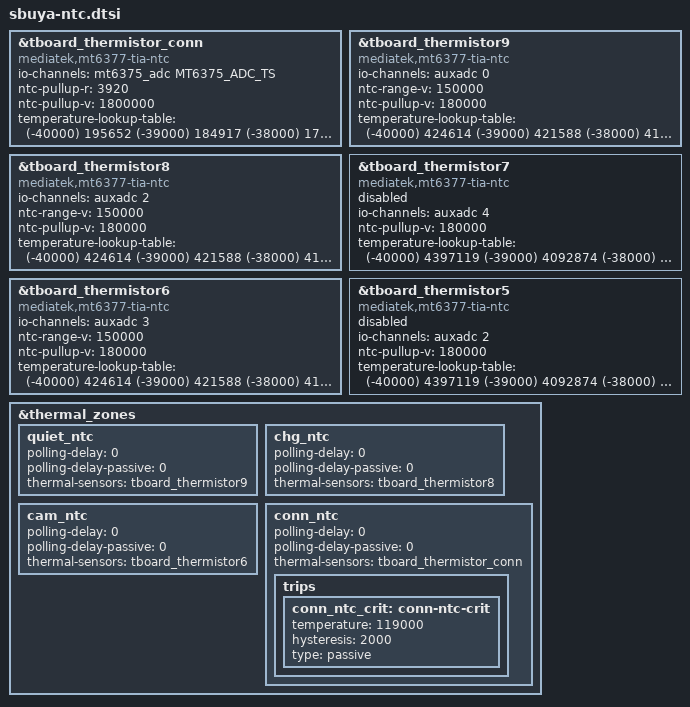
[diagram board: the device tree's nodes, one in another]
#include <dt-bindings/iio/mt635x-auxadc.h>
#include <dt-bindings/iio/adc/mediatek,mt6375_adc.h>

&tboard_thermistor_conn {
	compatible = "mediatek,mt6377-tia-ntc";
	#thermal-sensor-cells = <0>;
	io-channels = <&mt6375_adc MT6375_ADC_TS>;
	io-channel-names = "CONN_NTC";
	ntc-pullup-r = <3920>;
	ntc-pullup-v = <1800000>;
	temperature-lookup-table = <
		(-40000) 195652
		(-39000) 184917
		(-38000) 174845
		(-37000) 165391
		(-36000) 156512
		(-35000) 148171
		(-34000) 140330
		(-33000) 132957
		(-32000) 126021
		(-31000) 119493
		(-30000) 113347
		(-29000) 107564
		(-28000) 102115
		(-27000) 96977
		(-26000) 92131
		(-25000) 87558
		(-24000) 83242
		(-23000) 79166
		(-22000) 75315
		(-21000) 71676
		(-20000) 68236
		(-19000) 64990
		(-18000) 61919
		(-17000) 59011
		(-16000) 56257
		(-15000) 53649
		(-14000) 51177
		(-13000) 48834
		(-12000) 46613
		(-11000) 44505
		(-10000) 42506
		(-9000) 40599
		(-8000) 38790
		(-7000) 37072
		(-6000) 35441
		(-5000) 33892
		(-4000) 32419
		(-3000) 31020
		(-2000) 29689
		(-1000) 28423
		0 27218
		1000 26076
		2000 24987
		3000 23950
		4000 22962
		5000 22021
		6000 21123
		7000 20266
		8000 19449
		9000 18669
		10000 17925
		11000 17213
		12000 16534
		13000 15885
		14000 15265
		15000 14673
		16000 14107
		17000 13566
		18000 13048
		19000 12554
		20000 12080
		21000 11628
		22000 11194
		23000 10779
		24000 10381
		25000 10000
		26000 9634
		27000 9283
		28000 8947
		29000 8624
		30000 8314
		31000 8018
		32000 7733
		33000 7460
		34000 7199
		35000 6947
		36000 6706
		37000 6475
		38000 6252
		39000 6039
		40000 5833
		41000 5635
		42000 5445
		43000 5262
		44000 5086
		45000 4916
		46000 4753
		47000 4597
		48000 4446
		49000 4300
		50000 4160
		51000 4026
		52000 3896
		53000 3771
		54000 3651
		55000 3535
		56000 3423
		57000 3315
		58000 3211
		59000 3111
		60000 3014
		61000 2922
		62000 2833
		63000 2748
		64000 2665
		65000 2586
		66000 2509
		67000 2435
		68000 2363
		69000 2294
		70000 2227
		71000 2162
		72000 2100
		73000 2039
		74000 1981
		75000 1924
		76000 1869
		77000 1817
		78000 1765
		79000 1716
		80000 1668
		81000 1622
		82000 1577
		83000 1534
		84000 1492
		85000 1452
		86000 1412
		87000 1374
		88000 1338
		89000 1302
		90000 1268
		91000 1234
		92000 1201
		93000 1170
		94000 1139
		95000 1109
		96000 1080
		97000 1052
		98000 1025
		99000 999
		100000 973
		101000 949
		102000 925
		103000 902
		104000 879
		105000 858
		106000 836
		107000 816
		108000 796
		109000 776
		110000 758
		111000 739
		112000 721
		113000 704
		114000 687
		115000 671
		116000 655
		117000 640
		118000 625
		119000 610
		120000 596
		121000 582
		122000 569
		123000 556
		124000 543
		125000 531>;
};


/*[TN.NJDC] ntc overlay file.start*/
&tboard_thermistor9 {
	compatible = "mediatek,mt6377-tia-ntc";
	io-channels = <&auxadc 0>;
	io-channel-names = "QUIET_NTC";
	ntc-range-v = <150000>;
	ntc-pullup-v = <180000>;
	#thermal-sensor-cells = <0>;
	temperature-lookup-table = <
		(-40000) 424614
		(-39000) 421588
		(-38000) 418409
		(-37000) 415074
		(-36000) 411580
		(-35000) 407925
		(-34000) 404107
		(-33000) 400124
		(-32000) 395975
		(-31000) 391660
		(-30000) 387180
		(-29000) 382534
		(-28000) 377725
		(-27000) 372755
		(-26000) 367626
		(-25000) 362343
		(-24000) 356898
		(-23000) 351308
		(-22000) 345578
		(-21000) 339716
		(-20000) 333729
		(-19000) 327625
		(-18000) 321412
		(-17000) 315100
		(-16000) 308698
		(-15000) 302217
		(-14000) 295666
		(-13000) 289058
		(-12000) 282403
		(-11000) 275712
		(-10000) 268997
		(-9000) 262259
		(-8000) 255520
		(-7000) 248791
		(-6000) 242083
		(-5000) 235407
		(-4000) 228783
		(-3000) 222210
		(-2000) 215698
		(-1000) 209256
		0 202894
		1000 196611
		2000 190423
		3000 184336
		4000 178357
		5000 172491
		6000 166744
		7000 161118
		8000 155618
		9000 150248
		10000 145008
		11000 139902
		12000 134931
		13000 130096
		14000 125397
		15000 120834
		16000 116405
		17000 112112
		18000 107953
		19000 103927
		20000 100033
		21000 96268
		22000 92631
		23000 89118
		24000 85727
		25000 82456
		26000 79302
		27000 76261
		28000 73332
		29000 70511
		30000 67794
		31000 65180
		32000 62665
		33000 60246
		34000 57920
		35000 55683
		36000 53534
		37000 51468
		38000 49483
		39000 47576
		40000 45744
		41000 43987
		42000 42299
		43000 40678
		44000 39122
		45000 37629
		46000 36193
		47000 34816
		48000 33493
		49000 32223
		50000 31005
		51000 29837
		52000 28715
		53000 27639
		54000 26606
		55000 25614
		56000 24663
		57000 23749
		58000 22872
		59000 22029
		60000 21221
		61000 20445
		62000 19699
		63000 18983
		64000 18295
		65000 17635
		66000 17002
		67000 16394
		68000 15810
		69000 15248
		70000 14709
		71000 14189
		72000 13690
		73000 13210
		74000 12748
		75000 12305
		76000 11879
		77000 11470
		78000 11076
		79000 10698
		80000 10333
		81000 9983
		82000 9646
		83000 9321
		84000 9009
		85000 8708
		86000 8419
		87000 8140
		88000 7871
		89000 7613
		90000 7364
		91000 7125
		92000 6894
		93000 6672
		94000 6458
		95000 6252
		96000 6053
		97000 5860
		98000 5675
		99000 5496
		100000 5323
		101000 5157
		102000 4997
		103000 4843
		104000 4694
		105000 4550
		106000 4411
		107000 4277
		108000 4147
		109000 4022
		110000 3902
		111000 3785
		112000 3672
		113000 3563
		114000 3458
		115000 3356
		116000 3258
		117000 3164
		118000 3072
		119000 2984
		120000 2898
		121000 2815
		122000 2735
		123000 2657
		124000 2582
		125000 2509>;
};
&tboard_thermistor8 {
	compatible = "mediatek,mt6377-tia-ntc";
	io-channels = <&auxadc 2>;
	io-channel-names = "CHG_NTC";
	ntc-range-v = <150000>;
	ntc-pullup-v = <180000>;
	#thermal-sensor-cells = <0>;
	temperature-lookup-table = <
		(-40000) 424614
		(-39000) 421588
		(-38000) 418409
		(-37000) 415074
		(-36000) 411580
		(-35000) 407925
		(-34000) 404107
		(-33000) 400124
		(-32000) 395975
		(-31000) 391660
		(-30000) 387180
		(-29000) 382534
		(-28000) 377725
		(-27000) 372755
		(-26000) 367626
		(-25000) 362343
		(-24000) 356898
		(-23000) 351308
		(-22000) 345578
		(-21000) 339716
		(-20000) 333729
		(-19000) 327625
		(-18000) 321412
		(-17000) 315100
		(-16000) 308698
		(-15000) 302217
		(-14000) 295666
		(-13000) 289058
		(-12000) 282403
		(-11000) 275712
		(-10000) 268997
		(-9000) 262259
		(-8000) 255520
		(-7000) 248791
		(-6000) 242083
		(-5000) 235407
		(-4000) 228783
		(-3000) 222210
		(-2000) 215698
		(-1000) 209256
		0 202894
		1000 196611
		2000 190423
		3000 184336
		4000 178357
		5000 172491
		6000 166744
		7000 161118
		8000 155618
		9000 150248
		10000 145008
		11000 139902
		12000 134931
		13000 130096
		14000 125397
		15000 120834
		16000 116405
		17000 112112
		18000 107953
		19000 103927
		20000 100033
		21000 96268
		22000 92631
		23000 89118
		24000 85727
		25000 82456
		26000 79302
		27000 76261
		28000 73332
		29000 70511
		30000 67794
		31000 65180
		32000 62665
		33000 60246
		34000 57920
		35000 55683
		36000 53534
		37000 51468
		38000 49483
		39000 47576
		40000 45744
		41000 43987
		42000 42299
		43000 40678
		44000 39122
		45000 37629
		46000 36193
		47000 34816
		48000 33493
		49000 32223
		50000 31005
		51000 29837
		52000 28715
		53000 27639
		54000 26606
		55000 25614
		56000 24663
		57000 23749
		58000 22872
		59000 22029
		60000 21221
		61000 20445
		62000 19699
		63000 18983
		64000 18295
		65000 17635
		66000 17002
		67000 16394
		68000 15810
		69000 15248
		70000 14709
		71000 14189
		72000 13690
		73000 13210
		74000 12748
		75000 12305
		76000 11879
		77000 11470
		78000 11076
		79000 10698
		80000 10333
		81000 9983
		82000 9646
		83000 9321
		84000 9009
		85000 8708
		86000 8419
		87000 8140
		88000 7871
		89000 7613
		90000 7364
		91000 7125
		92000 6894
		93000 6672
		94000 6458
		95000 6252
		96000 6053
		97000 5860
		98000 5675
		99000 5496
		100000 5323
		101000 5157
		102000 4997
		103000 4843
		104000 4694
		105000 4550
		106000 4411
		107000 4277
		108000 4147
		109000 4022
		110000 3902
		111000 3785
		112000 3672
		113000 3563
		114000 3458
		115000 3356
		116000 3258
		117000 3164
		118000 3072
		119000 2984
		120000 2898
		121000 2815
		122000 2735
		123000 2657
		124000 2582
		125000 2509>;
};
&tboard_thermistor7 {
	status = "disabled";
	compatible = "mediatek,mt6377-tia-ntc";
	io-channels = <&auxadc 4>;
	io-channel-names = "SPK_NTC";
	ntc-pullup-v = <180000>;
	#thermal-sensor-cells = <0>;
	temperature-lookup-table = <
		(-40000) 4397119
		(-39000) 4092874
		(-38000) 3811717
		(-37000) 3551749
		(-36000) 3311236
		(-35000) 3088599
		(-34000) 2882396
		(-33000) 2691310
		(-32000) 2514137
		(-31000) 2349778
		(-30000) 2197225
		(-29000) 2055558
		(-28000) 1923932
		(-27000) 1801573
		(-26000) 1687773
		(-25000) 1581881
		(-24000) 1483100
		(-23000) 1391113
		(-22000) 1305413
		(-21000) 1225531
		(-20000) 1151037
		(-19000) 1081535
		(-18000) 1016661
		(-17000) 956080
		(-16000) 899481
		(-15000) 846579
		(-14000) 797111
		(-13000) 750834
		(-12000) 707524
		(-11000) 666972
		(-10000) 628988
		(-9000) 593342
		(-8000) 559931
		(-7000) 528602
		(-6000) 499212
		(-5000) 471632
		(-4000) 445772
		(-3000) 421480
		(-2000) 398652
		(-1000) 377193
		0 357012
		1000 338006
		2000 320122
		3000 303287
		4000 287434
		5000 272500
		6000 258426
		7000 245160
		8000 232649
		9000 220847
		10000 209710
		11000 199196
		12000 189268
		13000 179890
		14000 171027
		15000 162651
		16000 154726
		17000 147232
		18000 140142
		19000 133432
		20000 127080
		21000 121066
		22000 115368
		23000 109970
		24000 104852
		25000 100000
		26000 95398
		27000 91032
		28000 86889
		29000 82956
		30000 79222
		31000 75675
		32000 72306
		33000 69104
		34000 66061
		35000 63167
		36000 60415
		37000 57797
		38000 55306
		39000 52934
		40000 50677
		41000 48528
		42000 46482
		43000 44533
		44000 42675
		45000 40904
		46000 39213
		47000 37601
		48000 36063
		49000 34595
		50000 33195
		51000 31859
		52000 30584
		53000 29366
		54000 28203
		55000 27091
		56000 26028
		57000 25013
		58000 24042
		59000 23113
		60000 22224
		61000 21374
		62000 20560
		63000 19782
		64000 19036
		65000 18322
		66000 17640
		67000 16986
		68000 16360
		69000 15759
		70000 15184
		71000 14631
		72000 14100
		73000 13591
		74000 13103
		75000 12635
		76000 12187
		77000 11756
		78000 11343
		79000 10946
		80000 10565
		81000 10199
		82000 9847
		83000 9509
		84000 9184
		85000 8872
		86000 8572
		87000 8283
		88000 8005
		89000 7738
		90000 7481
		91000 7234
		92000 6997
		93000 6769
		94000 6548
		95000 6337
		96000 6132
		97000 5934
		98000 5744
		99000 5561
		100000 5384
		101000 5214
		102000 5051
		103000 4893
		104000 4741
		105000 4594
		106000 4453
		107000 4316
		108000 4184
		109000 4057
		110000 3934
		111000 3816
		112000 3701
		113000 3591
		114000 3484
		115000 3380
		116000 3281
		117000 3185
		118000 3093
		119000 3003
		120000 2916
		121000 2832
		122000 2751
		123000 2672
		124000 2596
		125000 2522>;
};
&tboard_thermistor6 {
	compatible = "mediatek,mt6377-tia-ntc";
	io-channels = <&auxadc 3>;
	io-channel-names = "CAM_NTC";
	ntc-range-v = <150000>;
	ntc-pullup-v = <180000>;
	#thermal-sensor-cells = <0>;
	temperature-lookup-table = <
		(-40000) 424614
		(-39000) 421588
		(-38000) 418409
		(-37000) 415074
		(-36000) 411580
		(-35000) 407925
		(-34000) 404107
		(-33000) 400124
		(-32000) 395975
		(-31000) 391660
		(-30000) 387180
		(-29000) 382534
		(-28000) 377725
		(-27000) 372755
		(-26000) 367626
		(-25000) 362343
		(-24000) 356898
		(-23000) 351308
		(-22000) 345578
		(-21000) 339716
		(-20000) 333729
		(-19000) 327625
		(-18000) 321412
		(-17000) 315100
		(-16000) 308698
		(-15000) 302217
		(-14000) 295666
		(-13000) 289058
		(-12000) 282403
		(-11000) 275712
		(-10000) 268997
		(-9000) 262259
		(-8000) 255520
		(-7000) 248791
		(-6000) 242083
		(-5000) 235407
		(-4000) 228783
		(-3000) 222210
		(-2000) 215698
		(-1000) 209256
		0 202894
		1000 196611
		2000 190423
		3000 184336
		4000 178357
		5000 172491
		6000 166744
		7000 161118
		8000 155618
		9000 150248
		10000 145008
		11000 139902
		12000 134931
		13000 130096
		14000 125397
		15000 120834
		16000 116405
		17000 112112
		18000 107953
		19000 103927
		20000 100033
		21000 96268
		22000 92631
		23000 89118
		24000 85727
		25000 82456
		26000 79302
		27000 76261
		28000 73332
		29000 70511
		30000 67794
		31000 65180
		32000 62665
		33000 60246
		34000 57920
		35000 55683
		36000 53534
		37000 51468
		38000 49483
		39000 47576
		40000 45744
		41000 43987
		42000 42299
		43000 40678
		44000 39122
		45000 37629
		46000 36193
		47000 34816
		48000 33493
		49000 32223
		50000 31005
		51000 29837
		52000 28715
		53000 27639
		54000 26606
		55000 25614
		56000 24663
		57000 23749
		58000 22872
		59000 22029
		60000 21221
		61000 20445
		62000 19699
		63000 18983
		64000 18295
		65000 17635
		66000 17002
		67000 16394
		68000 15810
		69000 15248
		70000 14709
		71000 14189
		72000 13690
		73000 13210
		74000 12748
		75000 12305
		76000 11879
		77000 11470
		78000 11076
		79000 10698
		80000 10333
		81000 9983
		82000 9646
		83000 9321
		84000 9009
		85000 8708
		86000 8419
		87000 8140
		88000 7871
		89000 7613
		90000 7364
		91000 7125
		92000 6894
		93000 6672
		94000 6458
		95000 6252
		96000 6053
		97000 5860
		98000 5675
		99000 5496
		100000 5323
		101000 5157
		102000 4997
		103000 4843
		104000 4694
		105000 4550
		106000 4411
		107000 4277
		108000 4147
		109000 4022
		110000 3902
		111000 3785
		112000 3672
		113000 3563
		114000 3458
		115000 3356
		116000 3258
		117000 3164
		118000 3072
		119000 2984
		120000 2898
		121000 2815
		122000 2735
		123000 2657
		124000 2582
		125000 2509>;
};
&tboard_thermistor5 {
	status = "disabled";
	compatible = "mediatek,mt6377-tia-ntc";
	io-channels = <&auxadc 2>;
	io-channel-names = "WCN_NTC";
	ntc-pullup-v = <180000>;
	#thermal-sensor-cells = <0>;
	temperature-lookup-table = <
		(-40000) 4397119
		(-39000) 4092874
		(-38000) 3811717
		(-37000) 3551749
		(-36000) 3311236
		(-35000) 3088599
		(-34000) 2882396
		(-33000) 2691310
		(-32000) 2514137
		(-31000) 2349778
		(-30000) 2197225
		(-29000) 2055558
		(-28000) 1923932
		(-27000) 1801573
		(-26000) 1687773
		(-25000) 1581881
		(-24000) 1483100
		(-23000) 1391113
		(-22000) 1305413
		(-21000) 1225531
		(-20000) 1151037
		(-19000) 1081535
		(-18000) 1016661
		(-17000) 956080
		(-16000) 899481
		(-15000) 846579
		(-14000) 797111
		(-13000) 750834
		(-12000) 707524
		(-11000) 666972
		(-10000) 628988
		(-9000) 593342
		(-8000) 559931
		(-7000) 528602
		(-6000) 499212
		(-5000) 471632
		(-4000) 445772
		(-3000) 421480
		(-2000) 398652
		(-1000) 377193
		0 357012
		1000 338006
		2000 320122
		3000 303287
		4000 287434
		5000 272500
		6000 258426
		7000 245160
		8000 232649
		9000 220847
		10000 209710
		11000 199196
		12000 189268
		13000 179890
		14000 171027
		15000 162651
		16000 154726
		17000 147232
		18000 140142
		19000 133432
		20000 127080
		21000 121066
		22000 115368
		23000 109970
		24000 104852
		25000 100000
		26000 95398
		27000 91032
		28000 86889
		29000 82956
		30000 79222
		31000 75675
		32000 72306
		33000 69104
		34000 66061
		35000 63167
		36000 60415
		37000 57797
		38000 55306
		39000 52934
		40000 50677
		41000 48528
		42000 46482
		43000 44533
		44000 42675
		45000 40904
		46000 39213
		47000 37601
		48000 36063
		49000 34595
		50000 33195
		51000 31859
		52000 30584
		53000 29366
		54000 28203
		55000 27091
		56000 26028
		57000 25013
		58000 24042
		59000 23113
		60000 22224
		61000 21374
		62000 20560
		63000 19782
		64000 19036
		65000 18322
		66000 17640
		67000 16986
		68000 16360
		69000 15759
		70000 15184
		71000 14631
		72000 14100
		73000 13591
		74000 13103
		75000 12635
		76000 12187
		77000 11756
		78000 11343
		79000 10946
		80000 10565
		81000 10199
		82000 9847
		83000 9509
		84000 9184
		85000 8872
		86000 8572
		87000 8283
		88000 8005
		89000 7738
		90000 7481
		91000 7234
		92000 6997
		93000 6769
		94000 6548
		95000 6337
		96000 6132
		97000 5934
		98000 5744
		99000 5561
		100000 5384
		101000 5214
		102000 5051
		103000 4893
		104000 4741
		105000 4594
		106000 4453
		107000 4316
		108000 4184
		109000 4057
		110000 3934
		111000 3816
		112000 3701
		113000 3591
		114000 3484
		115000 3380
		116000 3281
		117000 3185
		118000 3093
		119000 3003
		120000 2916
		121000 2832
		122000 2751
		123000 2672
		124000 2596
		125000 2522>;
};

&thermal_zones {
	quiet_ntc: quiet_ntc {
		polling-delay = <0>; /* milliseconds */
		polling-delay-passive = <0>; /* milliseconds */
		thermal-sensors = <&tboard_thermistor9>;
	};
	chg_ntc: chg_ntc {
		polling-delay = <0>; /* milliseconds */
		polling-delay-passive = <0>; /* milliseconds */
		thermal-sensors = <&tboard_thermistor8>;
	};
	cam_ntc: cam_ntc {
		polling-delay = <0>; /* milliseconds */
		polling-delay-passive = <0>; /* milliseconds */
		thermal-sensors = <&tboard_thermistor6>;
	};
	conn_ntc: conn_ntc {
		polling-delay = <0>; /* milliseconds */
		polling-delay-passive = <0>; /* milliseconds */
		thermal-sensors = <&tboard_thermistor_conn>;

		trips {
			conn_ntc_crit: conn-ntc-crit {
				temperature = <119000>;
				hysteresis = <2000>;
				type = "passive";
			};
		};
	};
};
/*[TN.NJDC] ntc overlay file.end*/
